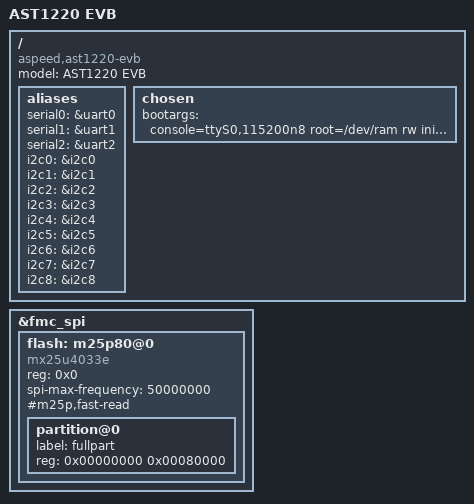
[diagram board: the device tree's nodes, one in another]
/dts-v1/;

#include "ast1220.dtsi"

/ {
	model = "AST1220 EVB";
	compatible = "aspeed,ast1220-evb", "aspeed,ast1220";

	aliases {
		serial0 = &uart0;
		serial1 = &uart1;
		serial2 = &uart2;
		i2c0 = &i2c0;
		i2c1 = &i2c1;
		i2c2 = &i2c2;
		i2c3 = &i2c3;
		i2c4 = &i2c4;
		i2c5 = &i2c5;
		i2c6 = &i2c6;
		i2c7 = &i2c7;
		i2c8 = &i2c8;
	};


	chosen {
		bootargs = "console=ttyS0,115200n8 root=/dev/ram rw init=/linuxrc";
	};

};

&fmc_spi {
	status = "okay";
	flash: m25p80@0 {
	compatible = "mx25u4033e", "m25p80", "jedec,spi-nor";
	reg = <0x0>;
	#address-cells = <0x1>;
	#size-cells = <0x1>;
	spi-max-frequency = <50000000>;
	#m25p,fast-read;
		partition@0 {
			label = "fullpart";
			reg = <0x00000000 0x00080000>;	
		};
	};
};
